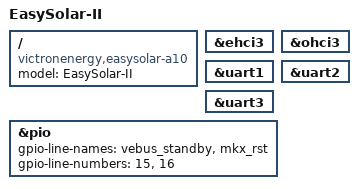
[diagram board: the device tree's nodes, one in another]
// SPDX-License-Identifier: GPL-2.0 OR X11
/*
 * Copyright (C) 2019 Mans Rullgard <mans@mansr.com>
 */

#include "sun8i-h3-nanopi-easysolar-base-a10.dtsi"
#include "victron-character-display.dtsi"

/ {
	model = "EasySolar-II";
	compatible = "victronenergy,easysolar-a10",
		     "friendlyarm,nanopi-neo-core",
		     "allwinner,sun8i-h3";
};

&ehci3 {
	status = "okay";
};

&ohci3 {
	status = "okay";
};

&uart1 {
	status = "okay";
};

&uart2 {
	status = "okay";
};

&uart3 {
	status = "okay";
};

&pio {
	gpio-line-names = "vebus_standby", "mkx_rst";
	gpio-line-numbers = <15>, <16>;
};
